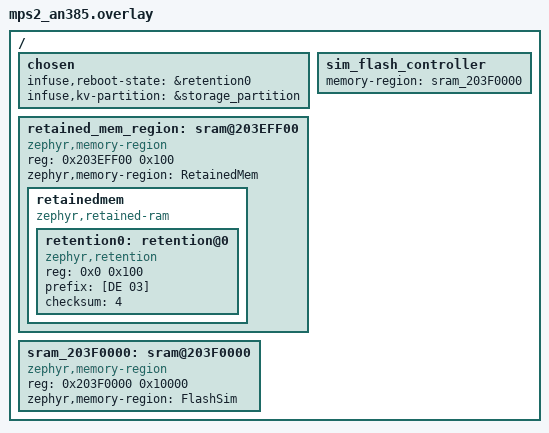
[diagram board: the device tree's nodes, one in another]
/*
 * Copyright (c) 2025 Embeint Holdings Pty Ltd
 * SPDX-License-Identifier: FSL-1.1-ALv2
 */

/ {
	chosen {
		infuse,reboot-state = &retention0;
		infuse,kv-partition = &storage_partition;
	};

	retained_mem_region: sram@203EFF00 {
		compatible = "zephyr,memory-region", "mmio-sram";
		reg = <0x203EFF00 0x100>;
		zephyr,memory-region = "RetainedMem";
		status = "okay";

		retainedmem {
			compatible = "zephyr,retained-ram";
			status = "okay";
			#address-cells = <1>;
			#size-cells = <1>;

			retention0: retention@0 {
					compatible = "zephyr,retention";
					status = "okay";
					reg = <0x0 0x100>;
					prefix = [DE 03];
					checksum = <4>;
			};
		};
	};

	/* Explicit memory region for simulated flash so its not zeroed on reboot */
	sram_203F0000:sram@203F0000 {
		compatible = "zephyr,memory-region", "mmio-sram";
		reg = <0x203F0000 0x10000>;
		zephyr,memory-region = "FlashSim";
		status = "okay";
	};

	sim_flash_controller {
		memory-region = <&sram_203F0000>;
	};
};
